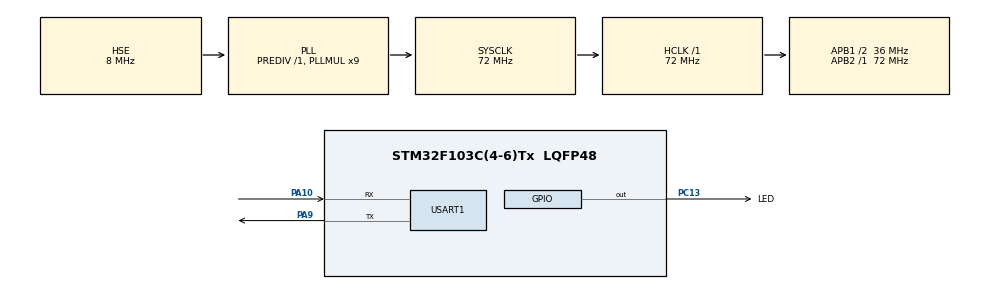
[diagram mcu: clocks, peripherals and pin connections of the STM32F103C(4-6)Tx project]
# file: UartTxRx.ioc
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FATFS._USE_LFN=1
Mcu.Family=STM32F1
Mcu.Name=STM32F103C(4-6)Tx
Mcu.Package=LQFP48
NVIC.PriorityGroup=NVIC_PRIORITYGROUP_4
NVIC.USART1_IRQn=true\:0\:0\:false\:false\:true\:true\:true
PA10.Mode=Asynchronous
PA10.Signal=USART1_RX
PA9.Mode=Asynchronous
PA9.Signal=USART1_TX
PC13-TAMPER-RTC.GPIO_Label=LED
PC13-TAMPER-RTC.GPIO_Speed=GPIO_SPEED_FREQ_HIGH
PC13-TAMPER-RTC.Signal=GPIO_Output
PD0-OSC_IN.Mode=HSE-External-Oscillator
PD0-OSC_IN.Signal=RCC_OSC_IN
PD1-OSC_OUT.Mode=HSE-External-Oscillator
PD1-OSC_OUT.Signal=RCC_OSC_OUT
ProjectManager.HeapSize=0x200
ProjectManager.StackSize=0x400
ProjectManager.TargetToolchain=STM32CubeIDE
RCC.AHBFreq_Value=72000000
RCC.APB1CLKDivider=RCC_HCLK_DIV2
RCC.APB1Freq_Value=36000000
RCC.APB1TimFreq_Value=72000000
RCC.APB2Freq_Value=72000000
RCC.APB2TimFreq_Value=72000000
RCC.HCLKFreq_Value=72000000
RCC.PLLMUL=RCC_PLL_MUL9
RCC.PLLSourceVirtual=RCC_PLLSOURCE_HSE
RCC.SYSCLKFreq_VALUE=72000000
RCC.SYSCLKSource=RCC_SYSCLKSOURCE_PLLCLK
RCC.USBFreq_Value=72000000
USART1.VirtualMode=VM_ASYNC
VP_FATFS_VS_Generic.Mode=User_defined
VP_SYS_VS_ND.Mode=No_Debug
board=custom

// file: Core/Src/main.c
/* USER CODE BEGIN Header */
/**
  ******************************************************************************
  * @file           : main.c
  * @brief          : Main program body
  ******************************************************************************
  * @attention
  *
  * <h2><center>&copy; Copyright (c) 2024 STMicroelectronics.
  * All rights reserved.</center></h2>
  *
  * This software component is licensed by ST under BSD 3-Clause license,
  * the "License"; You may not use this file except in compliance with the
  * License. You may obtain a copy of the License at:
  *                        opensource.org/licenses/BSD-3-Clause
  *
  ******************************************************************************
  */
/* USER CODE END Header */
#include "main.h"
#include "fatfs.h"

/* USER CODE BEGIN Includes */
#include <string.h>
#include <stdlib.h>
#include <stdint.h>
/* USER CODE END Includes */

UART_HandleTypeDef huart1;

/* USER CODE BEGIN PV */
uint8_t UartBuf[10];
uint8_t ret;

FATFS fs;
FIL fil;
FRESULT fresult;
char buffer[1024];
UINT br, bw;

FATFS *ptr;
DWORD fre_clust;
/* USER CODE END PV */

void SystemClock_Config(void);
static void MX_GPIO_Init(void);
static void MX_USART1_UART_Init(void);

/* USER CODE BEGIN 0 */
void send_uart (char *string)
{
	uint8_t len = strlen(string);
	HAL_UART_Transmit(&huart1, (uint8_t *) string, len, 2000);
}

int bufsize (char *buf)
{
	int i=0;
	while (*buf++ != '\0') i++;
	return i;
}

void bufclear (void)
{
	int i;
	for(i=0; i<1024; i++)
	{
		buffer[i]= '\0';
	}
}
/* USER CODE END 0 */

int main(void)
{

  /* MCU Configuration--------------------------------------------------------*/

  /* Reset of all peripherals, Initializes the Flash interface and the Systick. */
  HAL_Init();

  /* Configure the system clock */
  SystemClock_Config();

  /* USER CODE BEGIN SysInit */
HAL_UART_Receive_IT(&huart1, UartBuf, sizeof(UartBuf));
  /* USER CODE END SysInit */

  /* Initialize all configured peripherals */
  MX_GPIO_Init();
  MX_USART1_UART_Init();
  MX_FATFS_Init();
  fresult = f_open(&fil,"file.txt",FA_OPEN_ALWAYS | FA_READ | FA_WRITE);
  fresult = f_puts("data from first file", &fil);
  fresult = f_close(&fil);

  fresult = f_open(&fil, "file.txt",FA_READ);

  f_gets(buffer,fil.fsize,&fil);
  send_uart(buffer);
  f_close(&fil);
  bufclear();

  /* Infinite loop */
  /* USER CODE BEGIN WHILE */
  while (1)
  {
	 ret= memcmp(&UartBuf,"led on",6); /****compare string and if match turn on led**/

	 if(ret==1)
	 {
		 HAL_GPIO_WritePin(GPIOC, GPIO_PIN_13, 1);
	 }
	 else
	 {
		 HAL_GPIO_WritePin(GPIOC, GPIO_PIN_13, 0);
	 }
    /* USER CODE END WHILE */

  }
}

void SystemClock_Config(void)
{
  RCC_OscInitTypeDef RCC_OscInitStruct = {0};
  RCC_ClkInitTypeDef RCC_ClkInitStruct = {0};

  /** Initializes the RCC Oscillators according to the specified parameters
  * in the RCC_OscInitTypeDef structure.
  */
  RCC_OscInitStruct.OscillatorType = RCC_OSCILLATORTYPE_HSE;
  RCC_OscInitStruct.HSEState = RCC_HSE_ON;
  RCC_OscInitStruct.HSEPredivValue = RCC_HSE_PREDIV_DIV1;
  RCC_OscInitStruct.HSIState = RCC_HSI_ON;
  RCC_OscInitStruct.PLL.PLLState = RCC_PLL_ON;
  RCC_OscInitStruct.PLL.PLLSource = RCC_PLLSOURCE_HSE;
  RCC_OscInitStruct.PLL.PLLMUL = RCC_PLL_MUL9;
  if (HAL_RCC_OscConfig(&RCC_OscInitStruct) != HAL_OK)
  {
    Error_Handler();
  }
  /** Initializes the CPU, AHB and APB buses clocks
  */
  RCC_ClkInitStruct.ClockType = RCC_CLOCKTYPE_HCLK|RCC_CLOCKTYPE_SYSCLK
                              |RCC_CLOCKTYPE_PCLK1|RCC_CLOCKTYPE_PCLK2;
  RCC_ClkInitStruct.SYSCLKSource = RCC_SYSCLKSOURCE_PLLCLK;
  RCC_ClkInitStruct.AHBCLKDivider = RCC_SYSCLK_DIV1;
  RCC_ClkInitStruct.APB1CLKDivider = RCC_HCLK_DIV2;
  RCC_ClkInitStruct.APB2CLKDivider = RCC_HCLK_DIV1;

  if (HAL_RCC_ClockConfig(&RCC_ClkInitStruct, FLASH_LATENCY_2) != HAL_OK)
  {
    Error_Handler();
  }
}

static void MX_USART1_UART_Init(void)
{

  huart1.Instance = USART1;
  huart1.Init.BaudRate = 115200;
  huart1.Init.WordLength = UART_WORDLENGTH_8B;
  huart1.Init.StopBits = UART_STOPBITS_1;
  huart1.Init.Parity = UART_PARITY_NONE;
  huart1.Init.Mode = UART_MODE_TX_RX;
  huart1.Init.HwFlowCtl = UART_HWCONTROL_NONE;
  huart1.Init.OverSampling = UART_OVERSAMPLING_16;
  if (HAL_UART_Init(&huart1) != HAL_OK)
  {
    Error_Handler();
  }

}

static void MX_GPIO_Init(void)
{
  GPIO_InitTypeDef GPIO_InitStruct = {0};

  /* GPIO Ports Clock Enable */
  __HAL_RCC_GPIOC_CLK_ENABLE();
  __HAL_RCC_GPIOD_CLK_ENABLE();
  __HAL_RCC_GPIOA_CLK_ENABLE();

  /*Configure GPIO pin Output Level */
  HAL_GPIO_WritePin(LED_GPIO_Port, LED_Pin, GPIO_PIN_RESET);

  /*Configure GPIO pin : LED_Pin */
  GPIO_InitStruct.Pin = LED_Pin;
  GPIO_InitStruct.Mode = GPIO_MODE_OUTPUT_PP;
  GPIO_InitStruct.Pull = GPIO_NOPULL;
  GPIO_InitStruct.Speed = GPIO_SPEED_FREQ_HIGH;
  HAL_GPIO_Init(LED_GPIO_Port, &GPIO_InitStruct);

}

void Error_Handler(void)
{
  __disable_irq();
  while (1)
  {
  }
}

/************************ (C) COPYRIGHT STMicroelectronics *****END OF FILE****/
